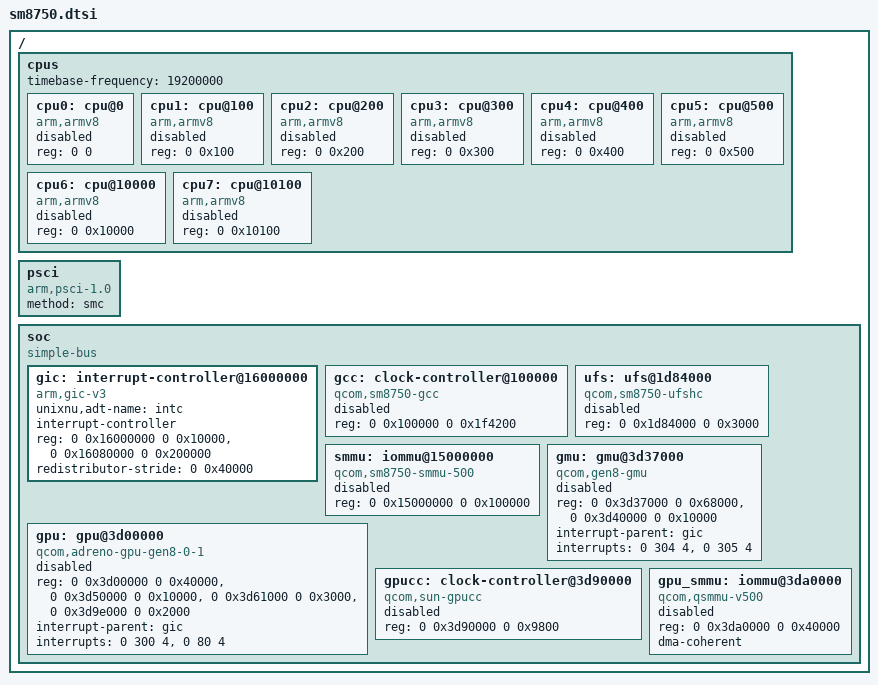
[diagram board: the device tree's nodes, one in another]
/ {
    #address-cells = <2>;
    #size-cells = <2>;
    cpus {
        #address-cells = <2>;
        #size-cells = <0>;
        timebase-frequency = <19200000>;
        cpu0: cpu@0 {
            device_type = "cpu";
            compatible = "arm,armv8";
            reg = <0 0>;
            status = "disabled";
        };
        cpu1: cpu@100 {
            device_type = "cpu";
            compatible = "arm,armv8";
            reg = <0 0x100>;
            status = "disabled";
        };
        cpu2: cpu@200 {
            device_type = "cpu";
            compatible = "arm,armv8";
            reg = <0 0x200>;
            status = "disabled";
        };
        cpu3: cpu@300 {
            device_type = "cpu";
            compatible = "arm,armv8";
            reg = <0 0x300>;
            status = "disabled";
        };
        cpu4: cpu@400 {
            device_type = "cpu";
            compatible = "arm,armv8";
            reg = <0 0x400>;
            status = "disabled";
        };
        cpu5: cpu@500 {
            device_type = "cpu";
            compatible = "arm,armv8";
            reg = <0 0x500>;
            status = "disabled";
        };
        cpu6: cpu@10000 {
            device_type = "cpu";
            compatible = "arm,armv8";
            reg = <0 0x10000>;
            status = "disabled";
        };
        cpu7: cpu@10100 {
            device_type = "cpu";
            compatible = "arm,armv8";
            reg = <0 0x10100>;
            status = "disabled";
        };
    };
    psci {
        compatible = "arm,psci-1.0";
        method = "smc";
    };
    soc {
        compatible = "simple-bus";
        #address-cells = <2>;
        #size-cells = <2>;
        ranges;
        gic: interrupt-controller@16000000 {
            compatible = "arm,gic-v3";
            unixnu,adt-name = "intc";
            interrupt-controller;
            #interrupt-cells = <3>;
            #address-cells = <0>;
            reg = <0 0x16000000 0 0x10000>, <0 0x16080000 0 0x200000>;
            redistributor-stride = <0 0x40000>;
        };
        gcc: clock-controller@100000 {
            compatible = "qcom,sm8750-gcc";
            reg = <0 0x100000 0 0x1f4200>;
            #clock-cells = <1>;
            status = "disabled";
        };
        ufs: ufs@1d84000 {
            compatible = "qcom,sm8750-ufshc";
            reg = <0 0x1d84000 0 0x3000>;
            status = "disabled";
        };
        smmu: iommu@15000000 {
            compatible = "qcom,sm8750-smmu-500";
            reg = <0 0x15000000 0 0x100000>;
            #iommu-cells = <1>;
            status = "disabled";
        };
        gpu: gpu@3d00000 {
            compatible = "qcom,adreno-gpu-gen8-0-1", "qcom,kgsl-3d0";
            reg = <0 0x3d00000 0 0x40000>,
                  <0 0x3d50000 0 0x10000>,
                  <0 0x3d61000 0 0x3000>,
                  <0 0x3d9e000 0 0x2000>;
            reg-names = "kgsl_3d0_reg_memory", "rscc", "cx_dbgc", "cx_misc";
            interrupt-parent = <&gic>;
            interrupts = <0 300 4>, <0 80 4>;
            interrupt-names = "kgsl_3d0_irq", "cx_host_irq";
            status = "disabled";
        };
        gmu: gmu@3d37000 {
            compatible = "qcom,gen8-gmu";
            reg = <0 0x3d37000 0 0x68000>, <0 0x3d40000 0 0x10000>;
            reg-names = "gmu", "gmu_ao_blk_dec0";
            interrupt-parent = <&gic>;
            interrupts = <0 304 4>, <0 305 4>;
            interrupt-names = "hfi", "gmu";
            status = "disabled";
        };
        gpucc: clock-controller@3d90000 {
            compatible = "qcom,sun-gpucc", "syscon";
            reg = <0 0x3d90000 0 0x9800>;
            #clock-cells = <1>;
            #power-domain-cells = <1>;
            #reset-cells = <1>;
            status = "disabled";
        };
        gpu_smmu: iommu@3da0000 {
            compatible = "qcom,qsmmu-v500", "qcom,adreno-smmu";
            reg = <0 0x3da0000 0 0x40000>;
            #iommu-cells = <2>;
            dma-coherent;
            status = "disabled";
        };
    };
};
